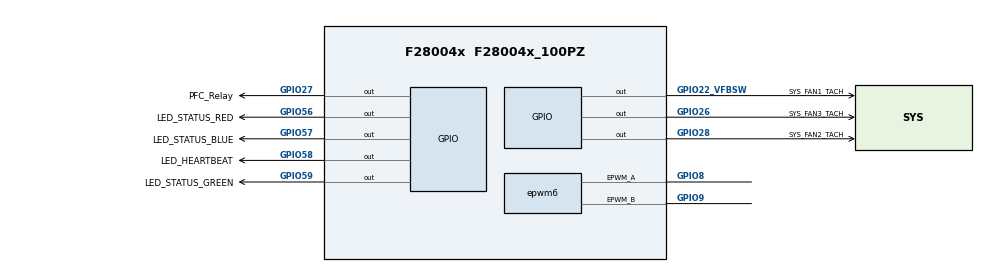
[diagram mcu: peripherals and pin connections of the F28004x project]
/**
 * @cliArgs --device "F28004x" --part "F28004x_100PZ" --package "F28004x_100PZ" --context "system" --product "C2000WARE@6.00.01.00"
 * @versions {"tool":"1.25.0+4268"}
 */

/**
 * Import the modules used in this configuration.
 */
const adc            = scripting.addModule("/driverlib/adc.js", {}, false);
const adc1           = adc.addInstance();
const adc2           = adc.addInstance();
const adc3           = adc.addInstance();
const cla            = scripting.addModule("/driverlib/cla.js", {}, false);
const cla1           = cla.addInstance();
const device_support = scripting.addModule("/driverlib/device_support.js");
const epwm           = scripting.addModule("/driverlib/epwm.js", {}, false);
const epwm1          = epwm.addInstance();
const epwm2          = epwm.addInstance();
const epwm3          = epwm.addInstance();
const epwm4          = epwm.addInstance();
const epwm5          = epwm.addInstance();
const epwm6          = epwm.addInstance();
const epwm7          = epwm.addInstance();
const gpio           = scripting.addModule("/driverlib/gpio.js", {}, false);
const gpio1          = gpio.addInstance();
const gpio2          = gpio.addInstance();
const gpio3          = gpio.addInstance();
const gpio4          = gpio.addInstance();
const gpio5          = gpio.addInstance();
const gpio6          = gpio.addInstance();
const gpio7          = gpio.addInstance();
const gpio8          = gpio.addInstance();
const memcfg         = scripting.addModule("/driverlib/memcfg.js");
const sync           = scripting.addModule("/driverlib/sync.js");

/**
 * Write custom configuration values to the imported modules.
 */
adc1.adcClockPrescaler              = "ADC_CLK_DIV_2_0";
adc1.$name                          = "myADCA";
adc1.enabledSOCs                    = ["ADC_SOC_NUMBER0","ADC_SOC_NUMBER1","ADC_SOC_NUMBER2","ADC_SOC_NUMBER3","ADC_SOC_NUMBER4","ADC_SOC_NUMBER5","ADC_SOC_NUMBER6","ADC_SOC_NUMBER7"];
adc1.soc0SampleWindow               = 20;
adc1.soc1SampleWindow               = 20;
adc1.soc0Channel                    = "ADC_CH_ADCIN1";
adc1.soc0Trigger                    = "ADC_TRIGGER_EPWM1_SOCA";
adc1.soc1Channel                    = "ADC_CH_ADCIN2";
adc1.soc2Channel                    = "ADC_CH_ADCIN3";
adc1.soc2SampleWindow               = 20;
adc1.soc3SampleWindow               = 20;
adc1.soc1Trigger                    = "ADC_TRIGGER_EPWM1_SOCA";
adc1.soc2Trigger                    = "ADC_TRIGGER_EPWM1_SOCA";
adc1.soc3Trigger                    = "ADC_TRIGGER_EPWM1_SOCA";
adc1.soc4Channel                    = "ADC_CH_ADCIN4";
adc1.soc4SampleWindow               = 20;
adc1.soc4Trigger                    = "ADC_TRIGGER_EPWM1_SOCA";
adc1.soc5Channel                    = "ADC_CH_ADCIN5";
adc1.soc5SampleWindow               = 20;
adc1.soc5Trigger                    = "ADC_TRIGGER_EPWM1_SOCA";
adc1.soc6SampleWindow               = 20;
adc1.soc6Trigger                    = "ADC_TRIGGER_EPWM1_SOCA";
adc1.soc7Channel                    = "ADC_CH_ADCIN10";
adc1.soc7SampleWindow               = 20;
adc1.soc6Channel                    = "ADC_CH_ADCIN6";
adc1.soc7Trigger                    = "ADC_TRIGGER_EPWM1_SOCA";
adc1.soc0Name                       = "V_LL_AB";
adc1.soc1Name                       = "V_LL_BC";
adc1.soc2Name                       = "V_LL_CA";
adc1.soc3Name                       = "V_Ref_1V5";
adc1.interruptPulseMode             = "ADC_PULSE_END_OF_CONV";
adc1.enabledInts                    = ["ADC_INT_NUMBER1"];
adc1.enableInterrupt1               = true;
adc1.interrupt1SOCSource            = "ADC_SOC_NUMBER7";
adc1.enableInterrupt1ContinuousMode = true;
adc1.registerInterrupts             = ["1"];
adc1.soc4Name                       = "T_LLC_Pri_MOS";
adc1.soc5Name                       = "T_LLC_Sec_MOS";
adc1.soc6Name                       = "T_Inv_3Ph_MOS";
adc1.soc7Name                       = "T_Ambient";
adc1.adcInt1.$name                  = "ADC_FrameDone_INT";
adc1.adcInt1.enableInterrupt        = true;
adc1.adcInt1.interruptHandler       = "ADC_FrameDone_INT";

adc2.adcClockPrescaler = "ADC_CLK_DIV_2_0";
adc2.$name             = "myADCB";
adc2.adcBase           = "ADCB_BASE";
adc2.enabledSOCs       = ["ADC_SOC_NUMBER0","ADC_SOC_NUMBER1","ADC_SOC_NUMBER2","ADC_SOC_NUMBER3"];
adc2.soc0SampleWindow  = 20;
adc2.soc0Trigger       = "ADC_TRIGGER_EPWM1_SOCA";
adc2.soc1Trigger       = "ADC_TRIGGER_EPWM1_SOCA";
adc2.soc1Name          = "V_DC800_CapU";
adc2.soc1SampleWindow  = 20;
adc2.soc2Name          = "V_DC800_CapL";
adc2.soc2SampleWindow  = 20;
adc2.soc2Trigger       = "ADC_TRIGGER_EPWM1_SOCA";
adc2.soc3Name          = "V_DC125";
adc2.soc3SampleWindow  = 20;
adc2.soc3Trigger       = "ADC_TRIGGER_EPWM1_SOCA";
adc2.soc0Name          = "I_DC800";
adc2.soc1Channel       = "ADC_CH_ADCIN2";
adc2.soc2Channel       = "ADC_CH_ADCIN3";
adc2.soc3Channel       = "ADC_CH_ADCIN4";

adc3.adcBase           = "ADCC_BASE";
adc3.adcClockPrescaler = "ADC_CLK_DIV_2_0";
adc3.enabledSOCs       = ["ADC_SOC_NUMBER0","ADC_SOC_NUMBER1","ADC_SOC_NUMBER2"];
adc3.soc0Name          = "I_Phase_A";
adc3.soc0SampleWindow  = 20;
adc3.soc0Trigger       = "ADC_TRIGGER_EPWM1_SOCA";
adc3.soc1Name          = "I_Phase_B";
adc3.soc1SampleWindow  = 20;
adc3.soc2Name          = "I_Phase_C";
adc3.soc2SampleWindow  = 20;
adc3.soc1Trigger       = "ADC_TRIGGER_EPWM1_SOCA";
adc3.soc2Trigger       = "ADC_TRIGGER_EPWM1_SOCA";
adc3.soc1Channel       = "ADC_CH_ADCIN1";
adc3.soc2Channel       = "ADC_CH_ADCIN2";
adc3.$name             = "myADCC";
adc3.enableInterrupt1  = true;

cla1.$name              = "myCLA0";
cla1.cpuint_CLA_TASK_1  = false;
cla1.cpuint_CLA_TASK_2  = false;
cla1.cpuint_CLA_TASK_3  = false;
cla1.cpuint_CLA_TASK_4  = false;
cla1.cpuint_CLA_TASK_5  = false;
cla1.cpuint_CLA_TASK_6  = false;
cla1.cpuint_CLA_TASK_7  = false;
cla1.cpuint_CLA_TASK_8  = false;
cla1.trigger_CLA_TASK_1 = "CLA_TRIGGER_EPWM1INT";

const divider3       = system.clockTree["PLL_ODIV"];
divider3.divideValue = 2;

const multiplier2         = system.clockTree["PLL_IMULT"];
multiplier2.multiplyValue = 25;

const mux2       = system.clockTree["OSCCLKSRCSEL"];
mux2.inputSelect = "X1_XTAL";

const pinFunction2     = system.clockTree["XTAL"];
pinFunction2.XTAL_Freq = 16;

epwm1.$name                                                      = "PFC_A";
epwm1.epwmTimebase_hsClockDiv                                    = "EPWM_HSCLOCK_DIVIDER_1";
epwm1.epwmTimebase_period                                        = 3125;
epwm1.epwmTimebase_counterMode                                   = "EPWM_COUNTER_MODE_UP_DOWN";
epwm1.epwmTimebase_syncOutPulseMode                              = "EPWM_SYNC_OUT_PULSE_ON_COUNTER_ZERO";
epwm1.epwmActionQualifier_EPWM_AQ_OUTPUT_A_ON_TIMEBASE_UP_CMPA   = "EPWM_AQ_OUTPUT_LOW";
epwm1.epwmActionQualifier_EPWM_AQ_OUTPUT_A_ON_TIMEBASE_DOWN_CMPA = "EPWM_AQ_OUTPUT_HIGH";
epwm1.epwmDeadband_polarityFED                                   = "EPWM_DB_POLARITY_ACTIVE_LOW";
epwm1.epwmDeadband_enableRED                                     = true;
epwm1.epwmDeadband_enableFED                                     = true;
epwm1.epwmDeadband_redShadowMode                                 = true;
epwm1.epwmDeadband_delayRED                                      = 150;
epwm1.epwmDeadband_fedShadowMode                                 = true;
epwm1.epwmDeadband_delayFED                                      = 150;
epwm1.epwmDeadband_dbControlGld                                  = true;
epwm1.epwmDeadband_fedGld                                        = true;
epwm1.epwmDeadband_redGld                                        = true;
epwm1.epwmTimebase_forceSyncPulse                                = true;
epwm1.epwmCounterCompare_cmpAGld                                 = true;
epwm1.epwmCounterCompare_cmpALink                                = "EPWM_LINK_WITH_EPWM_1";
epwm1.epwmCounterCompare_cmpA                                    = 1470;
epwm1.epwmEventTrigger_EPWM_SOC_A_triggerEnable                  = true;
epwm1.epwmEventTrigger_EPWM_SOC_A_triggerEventPrescalar          = "1";
epwm1.epwmEventTrigger_EPWM_SOC_A_triggerSource                  = "EPWM_SOC_TBCTR_ZERO";
epwm1.epwmEventTrigger_enableInterrupt                           = true;
epwm1.epwmEventTrigger_interruptSource                           = "EPWM_INT_TBCTR_ZERO";
epwm1.epwmEventTrigger_interruptEventCount                       = "1";
epwm1.epwmGlobalLoad_gld                                         = true;
epwm1.epwmGlobalLoad_gldPeriod                                   = "1";
epwm1.epwmGlobalLoad_globalePWMLoadLink                          = "EPWM_LINK_WITH_EPWM_1";
epwm1.epwm.$assign                                               = "EPWM1";

epwm2.epwmTimebase_hsClockDiv                                    = "EPWM_HSCLOCK_DIVIDER_1";
epwm2.epwmTimebase_period                                        = 3125;
epwm2.epwmTimebase_counterMode                                   = "EPWM_COUNTER_MODE_UP_DOWN";
epwm2.epwmCounterCompare_cmpA                                    = 1470;
epwm2.epwmActionQualifier_EPWM_AQ_OUTPUT_A_ON_TIMEBASE_UP_CMPA   = "EPWM_AQ_OUTPUT_LOW";
epwm2.epwmActionQualifier_EPWM_AQ_OUTPUT_A_ON_TIMEBASE_DOWN_CMPA = "EPWM_AQ_OUTPUT_HIGH";
epwm2.epwmDeadband_polarityFED                                   = "EPWM_DB_POLARITY_ACTIVE_LOW";
epwm2.epwmDeadband_enableRED                                     = true;
epwm2.epwmDeadband_enableFED                                     = true;
epwm2.epwmDeadband_redShadowMode                                 = true;
epwm2.epwmDeadband_delayRED                                      = 150;
epwm2.epwmDeadband_fedShadowMode                                 = true;
epwm2.epwmDeadband_delayFED                                      = 150;
epwm2.epwmDeadband_dbControlGld                                  = true;
epwm2.epwmDeadband_fedGld                                        = true;
epwm2.epwmDeadband_redGld                                        = true;
epwm2.$name                                                      = "PFC_B";
epwm2.epwmTimebase_phaseEnable                                   = true;
epwm2.epwmTimebase_counterModeAfterSync                          = "EPWM_COUNT_MODE_UP_AFTER_SYNC";
epwm2.epwmTimebase_syncOutPulseMode                              = "EPWM_SYNC_OUT_PULSE_ON_EPWMxSYNCIN";
epwm2.epwmCounterCompare_cmpAGld                                 = true;
epwm2.epwmCounterCompare_cmpALink                                = "EPWM_LINK_WITH_EPWM_2";
epwm2.epwmGlobalLoad_gld                                         = true;
epwm2.epwmGlobalLoad_gldPeriod                                   = "1";
epwm2.epwmGlobalLoad_globalePWMLoadLink                          = "EPWM_LINK_WITH_EPWM_1";
epwm2.epwm.$assign                                               = "EPWM2";

epwm3.epwmTimebase_hsClockDiv                                    = "EPWM_HSCLOCK_DIVIDER_1";
epwm3.epwmTimebase_period                                        = 3125;
epwm3.epwmTimebase_counterMode                                   = "EPWM_COUNTER_MODE_UP_DOWN";
epwm3.epwmCounterCompare_cmpA                                    = 1470;
epwm3.epwmActionQualifier_EPWM_AQ_OUTPUT_A_ON_TIMEBASE_UP_CMPA   = "EPWM_AQ_OUTPUT_LOW";
epwm3.epwmActionQualifier_EPWM_AQ_OUTPUT_A_ON_TIMEBASE_DOWN_CMPA = "EPWM_AQ_OUTPUT_HIGH";
epwm3.epwmDeadband_polarityFED                                   = "EPWM_DB_POLARITY_ACTIVE_LOW";
epwm3.epwmDeadband_enableRED                                     = true;
epwm3.epwmDeadband_enableFED                                     = true;
epwm3.epwmDeadband_redShadowMode                                 = true;
epwm3.epwmDeadband_delayRED                                      = 150;
epwm3.epwmDeadband_fedShadowMode                                 = true;
epwm3.epwmDeadband_delayFED                                      = 150;
epwm3.epwmDeadband_dbControlGld                                  = true;
epwm3.epwmDeadband_fedGld                                        = true;
epwm3.epwmDeadband_redGld                                        = true;
epwm3.epwmTimebase_phaseEnable                                   = true;
epwm3.epwmTimebase_counterModeAfterSync                          = "EPWM_COUNT_MODE_UP_AFTER_SYNC";
epwm3.epwmTimebase_syncOutPulseMode                              = "EPWM_SYNC_OUT_PULSE_ON_EPWMxSYNCIN";
epwm3.$name                                                      = "PFC_C";
epwm3.epwmCounterCompare_cmpAGld                                 = true;
epwm3.epwmCounterCompare_cmpALink                                = "EPWM_LINK_WITH_EPWM_3";
epwm3.epwmGlobalLoad_gld                                         = true;
epwm3.epwmGlobalLoad_gldPeriod                                   = "1";
epwm3.epwmGlobalLoad_globalePWMLoadLink                          = "EPWM_LINK_WITH_EPWM_1";

epwm4.$name                                                      = "LLC_PRI_A";
epwm4.epwmGlobalLoad_gld                                         = true;
epwm4.epwmGlobalLoad_gldPeriod                                   = "1";
epwm4.epwmTimebase_hsClockDiv                                    = "EPWM_HSCLOCK_DIVIDER_1";
epwm4.epwmTimebase_period                                        = 549;
epwm4.epwmTimebase_periodGld                                     = true;
epwm4.epwmTimebase_counterMode                                   = "EPWM_COUNTER_MODE_UP_DOWN";
epwm4.epwmTimebase_syncOutPulseMode                              = "EPWM_SYNC_OUT_PULSE_ON_COUNTER_ZERO";
epwm4.epwmCounterCompare_cmpA                                    = 274;
epwm4.epwmCounterCompare_cmpAGld                                 = true;
epwm4.epwmActionQualifier_EPWM_AQ_OUTPUT_A_ON_TIMEBASE_UP_CMPA   = "EPWM_AQ_OUTPUT_HIGH";
epwm4.epwmActionQualifier_EPWM_AQ_OUTPUT_A_ON_TIMEBASE_DOWN_CMPA = "EPWM_AQ_OUTPUT_LOW";
epwm4.epwmDeadband_polarityFED                                   = "EPWM_DB_POLARITY_ACTIVE_LOW";
epwm4.epwmDeadband_enableRED                                     = true;
epwm4.epwmDeadband_enableFED                                     = true;
epwm4.epwmDeadband_redShadowMode                                 = true;
epwm4.epwmDeadband_fedShadowMode                                 = true;
epwm4.epwmDeadband_delayRED                                      = 50;
epwm4.epwmDeadband_delayFED                                      = 50;
epwm4.epwmDeadband_outputSwapOutB                                = true;
epwm4.epwmDeadband_outputSwapOutA                                = true;
epwm4.epwm.$assign                                               = "EPWM4";

epwm5.epwmGlobalLoad_gld                                         = true;
epwm5.epwmGlobalLoad_gldPeriod                                   = "1";
epwm5.epwmTimebase_hsClockDiv                                    = "EPWM_HSCLOCK_DIVIDER_1";
epwm5.epwmTimebase_period                                        = 549;
epwm5.epwmTimebase_periodGld                                     = true;
epwm5.epwmTimebase_counterMode                                   = "EPWM_COUNTER_MODE_UP_DOWN";
epwm5.epwmCounterCompare_cmpA                                    = 274;
epwm5.epwmCounterCompare_cmpAGld                                 = true;
epwm5.epwmActionQualifier_EPWM_AQ_OUTPUT_A_ON_TIMEBASE_UP_CMPA   = "EPWM_AQ_OUTPUT_HIGH";
epwm5.epwmActionQualifier_EPWM_AQ_OUTPUT_A_ON_TIMEBASE_DOWN_CMPA = "EPWM_AQ_OUTPUT_LOW";
epwm5.epwmDeadband_polarityFED                                   = "EPWM_DB_POLARITY_ACTIVE_LOW";
epwm5.epwmDeadband_enableRED                                     = true;
epwm5.epwmDeadband_enableFED                                     = true;
epwm5.epwmDeadband_redShadowMode                                 = true;
epwm5.epwmDeadband_fedShadowMode                                 = true;
epwm5.epwmDeadband_delayRED                                      = 50;
epwm5.epwmDeadband_delayFED                                      = 50;
epwm5.epwmDeadband_outputSwapOutB                                = true;
epwm5.epwmDeadband_outputSwapOutA                                = true;
epwm5.$name                                                      = "LLC_PRI_B";
epwm5.epwmTimebase_phaseEnable                                   = true;
epwm5.epwmTimebase_phaseShift                                    = 183;
epwm5.epwmTimebase_syncOutPulseMode                              = "EPWM_SYNC_OUT_PULSE_ON_EPWMxSYNCIN";
epwm5.epwmGlobalLoad_globalePWMLoadLink                          = "EPWM_LINK_WITH_EPWM_4";
epwm5.epwm.$assign                                               = "EPWM7";

epwm6.$name                                                      = "LLC_SEC_A";
epwm6.epwmGlobalLoad_gld                                         = true;
epwm6.epwmGlobalLoad_gldPeriod                                   = "1";
epwm6.epwmTimebase_hsClockDiv                                    = "EPWM_HSCLOCK_DIVIDER_1";
epwm6.epwmTimebase_period                                        = 549;
epwm6.epwmTimebase_periodGld                                     = true;
epwm6.epwmTimebase_counterMode                                   = "EPWM_COUNTER_MODE_UP_DOWN";
epwm6.epwmTimebase_phaseEnable                                   = true;
epwm6.epwmTimebase_counterModeAfterSync                          = "EPWM_COUNT_MODE_UP_AFTER_SYNC";
epwm6.epwmTimebase_phaseShift                                    = 549;
epwm6.epwmTimebase_syncOutPulseMode                              = "EPWM_SYNC_OUT_PULSE_ON_EPWMxSYNCIN";
epwm6.epwmCounterCompare_cmpA                                    = 192;
epwm6.epwmCounterCompare_cmpAGld                                 = true;
epwm6.epwmCounterCompare_cmpB                                    = 357;
epwm6.epwmCounterCompare_cmpBGld                                 = true;
epwm6.epwmActionQualifier_EPWM_AQ_OUTPUT_A_gld                   = true;
epwm6.epwmActionQualifier_EPWM_AQ_OUTPUT_A_shadowMode            = true;
epwm6.epwmActionQualifier_EPWM_AQ_OUTPUT_A_ON_TIMEBASE_UP_CMPA   = "EPWM_AQ_OUTPUT_LOW";
epwm6.epwmActionQualifier_EPWM_AQ_OUTPUT_A_ON_TIMEBASE_DOWN_CMPA = "EPWM_AQ_OUTPUT_HIGH";
epwm6.epwmActionQualifier_EPWM_AQ_OUTPUT_B_shadowMode            = true;
epwm6.epwmActionQualifier_EPWM_AQ_OUTPUT_B_gld                   = true;
epwm6.epwmActionQualifier_EPWM_AQ_OUTPUT_B_ON_TIMEBASE_UP_CMPB   = "EPWM_AQ_OUTPUT_HIGH";
epwm6.epwmActionQualifier_EPWM_AQ_OUTPUT_B_ON_TIMEBASE_DOWN_CMPB = "EPWM_AQ_OUTPUT_LOW";
epwm6.epwmGlobalLoad_globalePWMLoadLink                          = "EPWM_LINK_WITH_EPWM_4";
epwm6.epwm.$assign                                               = "EPWM5";
epwm6.epwm.epwm_aPin.$assign                                     = "GPIO8";
epwm6.epwm.epwm_bPin.$assign                                     = "GPIO9";

epwm7.epwmGlobalLoad_gld                                         = true;
epwm7.epwmGlobalLoad_gldPeriod                                   = "1";
epwm7.epwmTimebase_hsClockDiv                                    = "EPWM_HSCLOCK_DIVIDER_1";
epwm7.epwmTimebase_period                                        = 549;
epwm7.epwmTimebase_periodGld                                     = true;
epwm7.epwmTimebase_counterMode                                   = "EPWM_COUNTER_MODE_UP_DOWN";
epwm7.epwmTimebase_phaseEnable                                   = true;
epwm7.epwmTimebase_syncOutPulseMode                              = "EPWM_SYNC_OUT_PULSE_ON_EPWMxSYNCIN";
epwm7.epwmCounterCompare_cmpA                                    = 192;
epwm7.epwmCounterCompare_cmpAGld                                 = true;
epwm7.epwmCounterCompare_cmpB                                    = 357;
epwm7.epwmCounterCompare_cmpBGld                                 = true;
epwm7.epwmActionQualifier_EPWM_AQ_OUTPUT_A_gld                   = true;
epwm7.epwmActionQualifier_EPWM_AQ_OUTPUT_A_shadowMode            = true;
epwm7.epwmActionQualifier_EPWM_AQ_OUTPUT_A_ON_TIMEBASE_UP_CMPA   = "EPWM_AQ_OUTPUT_LOW";
epwm7.epwmActionQualifier_EPWM_AQ_OUTPUT_A_ON_TIMEBASE_DOWN_CMPA = "EPWM_AQ_OUTPUT_HIGH";
epwm7.epwmActionQualifier_EPWM_AQ_OUTPUT_B_shadowMode            = true;
epwm7.epwmActionQualifier_EPWM_AQ_OUTPUT_B_gld                   = true;
epwm7.epwmActionQualifier_EPWM_AQ_OUTPUT_B_ON_TIMEBASE_UP_CMPB   = "EPWM_AQ_OUTPUT_HIGH";
epwm7.epwmActionQualifier_EPWM_AQ_OUTPUT_B_ON_TIMEBASE_DOWN_CMPB = "EPWM_AQ_OUTPUT_LOW";
epwm7.$name                                                      = "LLC_SEC_B";
epwm7.epwmTimebase_phaseShift                                    = 366;
epwm7.epwmGlobalLoad_globalePWMLoadLink                          = "EPWM_LINK_WITH_EPWM_4";
epwm7.epwm.$assign                                               = "EPWM8";

gpio1.$name             = "LED_STATUS_RED";
gpio1.writeInitialValue = true;
gpio1.direction         = "GPIO_DIR_MODE_OUT";
gpio1.gpioPin.$assign   = "GPIO56";

gpio2.writeInitialValue = true;
gpio2.direction         = "GPIO_DIR_MODE_OUT";
gpio2.$name             = "LED_STATUS_BLUE";
gpio2.gpioPin.$assign   = "GPIO57";

gpio3.writeInitialValue = true;
gpio3.direction         = "GPIO_DIR_MODE_OUT";
gpio3.$name             = "LED_STATUS_GREEN";
gpio3.gpioPin.$assign   = "GPIO59";

gpio4.$name             = "LED_HEARTBEAT";
gpio4.writeInitialValue = true;
gpio4.direction         = "GPIO_DIR_MODE_OUT";
gpio4.initialValue      = 1;
gpio4.gpioPin.$assign   = "GPIO58";

gpio5.$name             = "SYS_FAN1_TACH";
gpio5.writeInitialValue = true;
gpio5.gpioPin.$assign   = "GPIO22_VFBSW";

gpio6.$name             = "SYS_FAN2_TACH";
gpio6.writeInitialValue = true;
gpio6.gpioPin.$assign   = "GPIO28";

gpio7.writeInitialValue = true;
gpio7.$name             = "PFC_Relay";
gpio7.direction         = "GPIO_DIR_MODE_OUT";
gpio7.initialValue      = 1;
gpio7.gpioPin.$assign   = "GPIO27";

gpio8.writeInitialValue = true;
gpio8.$name             = "SYS_FAN3_TACH";
gpio8.gpioPin.$assign   = "GPIO26";

memcfg.config_MEMCFG_SECT_LS0        = "CLA_prog";
memcfg.config_MEMCFG_SECT_LS2        = "CLA_data";
memcfg.config_MEMCFG_SECT_LS3        = "CLA_data";
memcfg.init_MEMCFG_SECT_MSGCPUTOCLA1 = true;
memcfg.init_MEMCFG_SECT_MSGCLA1TOCPU = true;
memcfg.config_MEMCFG_SECT_LS7        = "CLA_data";
memcfg.config_MEMCFG_SECT_LS1        = "CLA_prog";

sync.epwm7SyncInSource = "SYSCTL_SYNC_IN_SRC_EPWM4SYNCOUT";

/**
 * Pinmux solution for unlocked pins/peripherals. This ensures that minor changes to the automatic solver in a future
 * version of the tool will not impact the pinmux you originally saw.  These lines can be completely deleted in order to
 * re-solve from scratch.
 */
epwm1.epwm.epwm_aPin.$suggestSolution = "GPIO0";
epwm1.epwm.epwm_bPin.$suggestSolution = "GPIO1";
epwm2.epwm.epwm_aPin.$suggestSolution = "GPIO2";
epwm2.epwm.epwm_bPin.$suggestSolution = "GPIO3";
epwm3.epwm.$suggestSolution           = "EPWM3";
epwm3.epwm.epwm_aPin.$suggestSolution = "GPIO4";
epwm3.epwm.epwm_bPin.$suggestSolution = "GPIO5";
epwm4.epwm.epwm_aPin.$suggestSolution = "GPIO6";
epwm4.epwm.epwm_bPin.$suggestSolution = "GPIO7";
epwm5.epwm.epwm_aPin.$suggestSolution = "GPIO12";
epwm5.epwm.epwm_bPin.$suggestSolution = "GPIO13";
epwm7.epwm.epwm_aPin.$suggestSolution = "GPIO14";
epwm7.epwm.epwm_bPin.$suggestSolution = "GPIO15";
